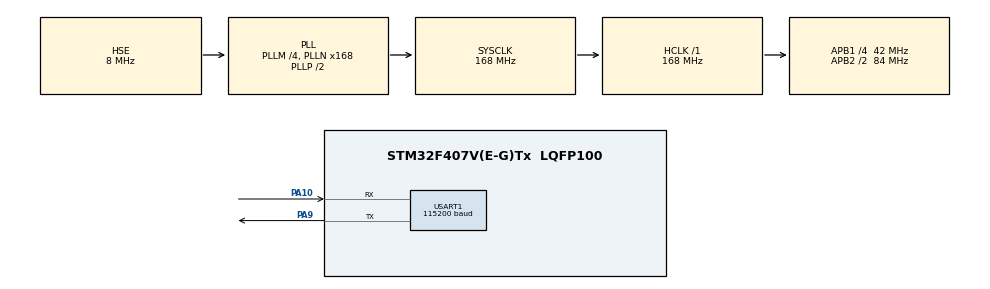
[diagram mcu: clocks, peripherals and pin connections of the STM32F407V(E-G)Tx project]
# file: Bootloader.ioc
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Mcu.Family=STM32F4
Mcu.Name=STM32F407V(E-G)Tx
Mcu.Package=LQFP100
NVIC.PriorityGroup=NVIC_PRIORITYGROUP_4
PA10.Mode=Asynchronous
PA10.Signal=USART1_RX
PA13.Mode=JTAG_5_pins
PA13.Signal=SYS_JTMS-SWDIO
PA14.Mode=JTAG_5_pins
PA14.Signal=SYS_JTCK-SWCLK
PA15.Mode=JTAG_5_pins
PA15.Signal=SYS_JTDI
PA9.Mode=Asynchronous
PA9.Signal=USART1_TX
PB3.Mode=JTAG_5_pins
PB3.Signal=SYS_JTDO-SWO
PB4.Mode=JTAG_5_pins
PB4.Signal=SYS_JTRST
PH0-OSC_IN.Mode=HSE-External-Oscillator
PH0-OSC_IN.Signal=RCC_OSC_IN
PH1-OSC_OUT.Mode=HSE-External-Oscillator
PH1-OSC_OUT.Signal=RCC_OSC_OUT
ProjectManager.HeapSize=0x200
ProjectManager.StackSize=0x400
ProjectManager.TargetToolchain=EWARM V8.50
RCC.48MHZClocksFreq_Value=48000000
RCC.AHBFreq_Value=168000000
RCC.APB1CLKDivider=RCC_HCLK_DIV4
RCC.APB1Freq_Value=42000000
RCC.APB1TimFreq_Value=84000000
RCC.APB2CLKDivider=RCC_HCLK_DIV2
RCC.APB2Freq_Value=84000000
RCC.APB2TimFreq_Value=168000000
RCC.CortexFreq_Value=168000000
RCC.HCLKFreq_Value=168000000
RCC.HSE_VALUE=8000000
RCC.HSI_VALUE=16000000
RCC.LSE_VALUE=32768
RCC.PLLM=4
RCC.PLLN=168
RCC.PLLQ=7
RCC.PLLSourceVirtual=RCC_PLLSOURCE_HSE
RCC.SYSCLKFreq_VALUE=168000000
RCC.SYSCLKSource=RCC_SYSCLKSOURCE_PLLCLK
RCC.VCOOutputFreq_Value=336000000
USART1.BaudRate=115200
USART1.VirtualMode=VM_ASYNC
VP_CRC_VS_CRC.Mode=CRC_Activate
VP_IWDG_VS_IWDG.Mode=IWDG_Activate
board=custom

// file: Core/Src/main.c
/* USER CODE BEGIN Header */
/**
  ******************************************************************************
  * @file           : main.c
  * @brief          : Main program body
  ******************************************************************************
  * @attention
  *
  * Copyright (c) 2025 STMicroelectronics.
  * All rights reserved.
  *
  * This software is licensed under terms that can be found in the LICENSE file
  * in the root directory of this software component.
  * If no LICENSE file comes with this software, it is provided AS-IS.
  *
  ******************************************************************************
  */
/* USER CODE END Header */
#include "main.h"
#include "crc.h"
#include "iwdg.h"
#include "usart.h"
#include "gpio.h"

/* USER CODE BEGIN PD */
#define APP_ADDRESS             0x08010000U  /* Application start address */
#define RAM_START_ADDRESS       0x20000000U  /* STM32F407 RAM start */
#define RAM_ADDRESS_MASK        0x2FFE0000U  /* Mask for RAM validation */
#define NVIC_ICER_COUNT         8U           /* Number of NVIC ICER registers */
/* USER CODE END PD */

void SystemClock_Config(void);
/* USER CODE BEGIN PFP */
static void JumpToApplication(void);
/* USER CODE END PFP */

int main(void)
{

  /* MCU Configuration--------------------------------------------------------*/

  /* Reset of all peripherals, Initializes the Flash interface and the Systick. */
  HAL_Init();

  /* Configure the system clock */
  SystemClock_Config();

  /* Initialize all configured peripherals */
  MX_GPIO_Init();
  MX_CRC_Init();

  MX_USART1_UART_Init();
  /* USER CODE BEGIN 2 */

  /* Jump to application - does not return if app is valid */
  JumpToApplication();

  /* If we reach here, application is invalid - stay in bootloader */

  /* USER CODE END 2 */

  /* Infinite loop */
  while (1)
  {

    /* USER CODE BEGIN 3 */
    /* Bootloader main loop - could add firmware update logic here */
  }
  /* USER CODE END 3 */
}

void SystemClock_Config(void)
{
  RCC_OscInitTypeDef RCC_OscInitStruct = {0};
  RCC_ClkInitTypeDef RCC_ClkInitStruct = {0};

  /** Configure the main internal regulator output voltage
  */
  __HAL_RCC_PWR_CLK_ENABLE();
  __HAL_PWR_VOLTAGESCALING_CONFIG(PWR_REGULATOR_VOLTAGE_SCALE1);

  /** Initializes the RCC Oscillators according to the specified parameters
  * in the RCC_OscInitTypeDef structure.
  */
  RCC_OscInitStruct.OscillatorType = RCC_OSCILLATORTYPE_LSI|RCC_OSCILLATORTYPE_HSE;
  RCC_OscInitStruct.HSEState = RCC_HSE_ON;
  RCC_OscInitStruct.LSIState = RCC_LSI_ON;
  RCC_OscInitStruct.PLL.PLLState = RCC_PLL_ON;
  RCC_OscInitStruct.PLL.PLLSource = RCC_PLLSOURCE_HSE;
  RCC_OscInitStruct.PLL.PLLM = 4;
  RCC_OscInitStruct.PLL.PLLN = 168;
  RCC_OscInitStruct.PLL.PLLP = RCC_PLLP_DIV2;
  RCC_OscInitStruct.PLL.PLLQ = 7;
  if (HAL_RCC_OscConfig(&RCC_OscInitStruct) != HAL_OK)
  {
    Error_Handler();
  }

  /** Initializes the CPU, AHB and APB buses clocks
  */
  RCC_ClkInitStruct.ClockType = RCC_CLOCKTYPE_HCLK|RCC_CLOCKTYPE_SYSCLK
                              |RCC_CLOCKTYPE_PCLK1|RCC_CLOCKTYPE_PCLK2;
  RCC_ClkInitStruct.SYSCLKSource = RCC_SYSCLKSOURCE_PLLCLK;
  RCC_ClkInitStruct.AHBCLKDivider = RCC_SYSCLK_DIV1;
  RCC_ClkInitStruct.APB1CLKDivider = RCC_HCLK_DIV4;
  RCC_ClkInitStruct.APB2CLKDivider = RCC_HCLK_DIV2;

  if (HAL_RCC_ClockConfig(&RCC_ClkInitStruct, FLASH_LATENCY_5) != HAL_OK)
  {
    Error_Handler();
  }
}

/* USER CODE BEGIN 4 */

/**
 * @brief  Jump to application at APP_ADDRESS
 * @note   This function does not return if application is valid
 * @retval None
 */
static void JumpToApplication(void)
{
    typedef void (*pFunction)(void);
    pFunction jump_to_app;
    uint32_t jump_address = 0U;
    uint32_t app_stack_pointer = 0U;
    uint32_t i = 0U;

    /* Get the application stack pointer (first entry in vector table) */
    app_stack_pointer = *(__IO uint32_t *)APP_ADDRESS;

    /* Check if valid stack pointer (must be in RAM: 0x20000000-0x2001FFFF for STM32F407) */
    if ((app_stack_pointer & RAM_ADDRESS_MASK) != RAM_START_ADDRESS)
    {
        /* Invalid application - stay in bootloader */
        return;
    }

    /* Get the application reset handler address (second entry in vector table) */
    jump_address = *(__IO uint32_t *)(APP_ADDRESS + 4U);
    jump_to_app = (pFunction)jump_address;

    /* Disable all interrupts */
    __disable_irq();

    /* Disable SysTick and clear pending interrupt */
    SysTick->CTRL = 0U;
    SysTick->LOAD = 0U;
    SysTick->VAL = 0U;

    /* Clear all pending interrupts */
    for (i = 0U; i < NVIC_ICER_COUNT; i++)
    {
        NVIC->ICER[i] = 0xFFFFFFFFU;
        NVIC->ICPR[i] = 0xFFFFFFFFU;
    }

    /* Set the vector table offset to application */
    SCB->VTOR = APP_ADDRESS;

    /* Set the main stack pointer to the application stack pointer */
    __set_MSP(app_stack_pointer);

    /* Jump to application reset handler */
    jump_to_app();

    /* Should never reach here - infinite loop as safety measure */
    for (;;)
    {
        /* Safety: halt if jump fails */
    }
}

/* USER CODE END 4 */

void Error_Handler(void)
{
  __disable_irq();
  while (1)
  {
  }
}
